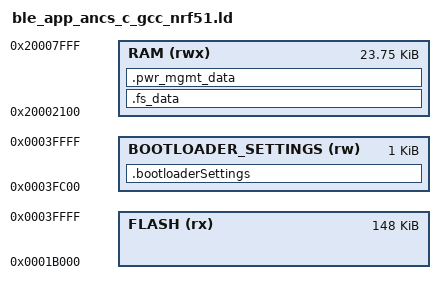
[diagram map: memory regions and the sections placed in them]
/* Linker script to configure memory regions. */

SEARCH_DIR(.)
GROUP(-lgcc -lc -lnosys)

MEMORY
{
  FLASH (rx) : ORIGIN = 0x1b000, LENGTH = 0x25000
  RAM (rwx) :  ORIGIN = 0x20002100, LENGTH = 0x5F00
  /** Location of bootloader setting in at the last flash page. */
  BOOTLOADER_SETTINGS (rw) : ORIGIN = 0x0003FC00, LENGTH = 0x0400
}

SECTIONS
{
  .fs_data :
  {
    PROVIDE(__start_fs_data = .);
    KEEP(*(.fs_data))
    PROVIDE(__stop_fs_data = .);
  } > RAM
  .pwr_mgmt_data :
  {
    PROVIDE(__start_pwr_mgmt_data = .);
    KEEP(*(.pwr_mgmt_data))
    PROVIDE(__stop_pwr_mgmt_data = .);
  } > RAM
  .bootloaderSettings(NOLOAD) :
  {

  } > BOOTLOADER_SETTINGS
} INSERT AFTER .data;

INCLUDE "nrf5x_common.ld"
